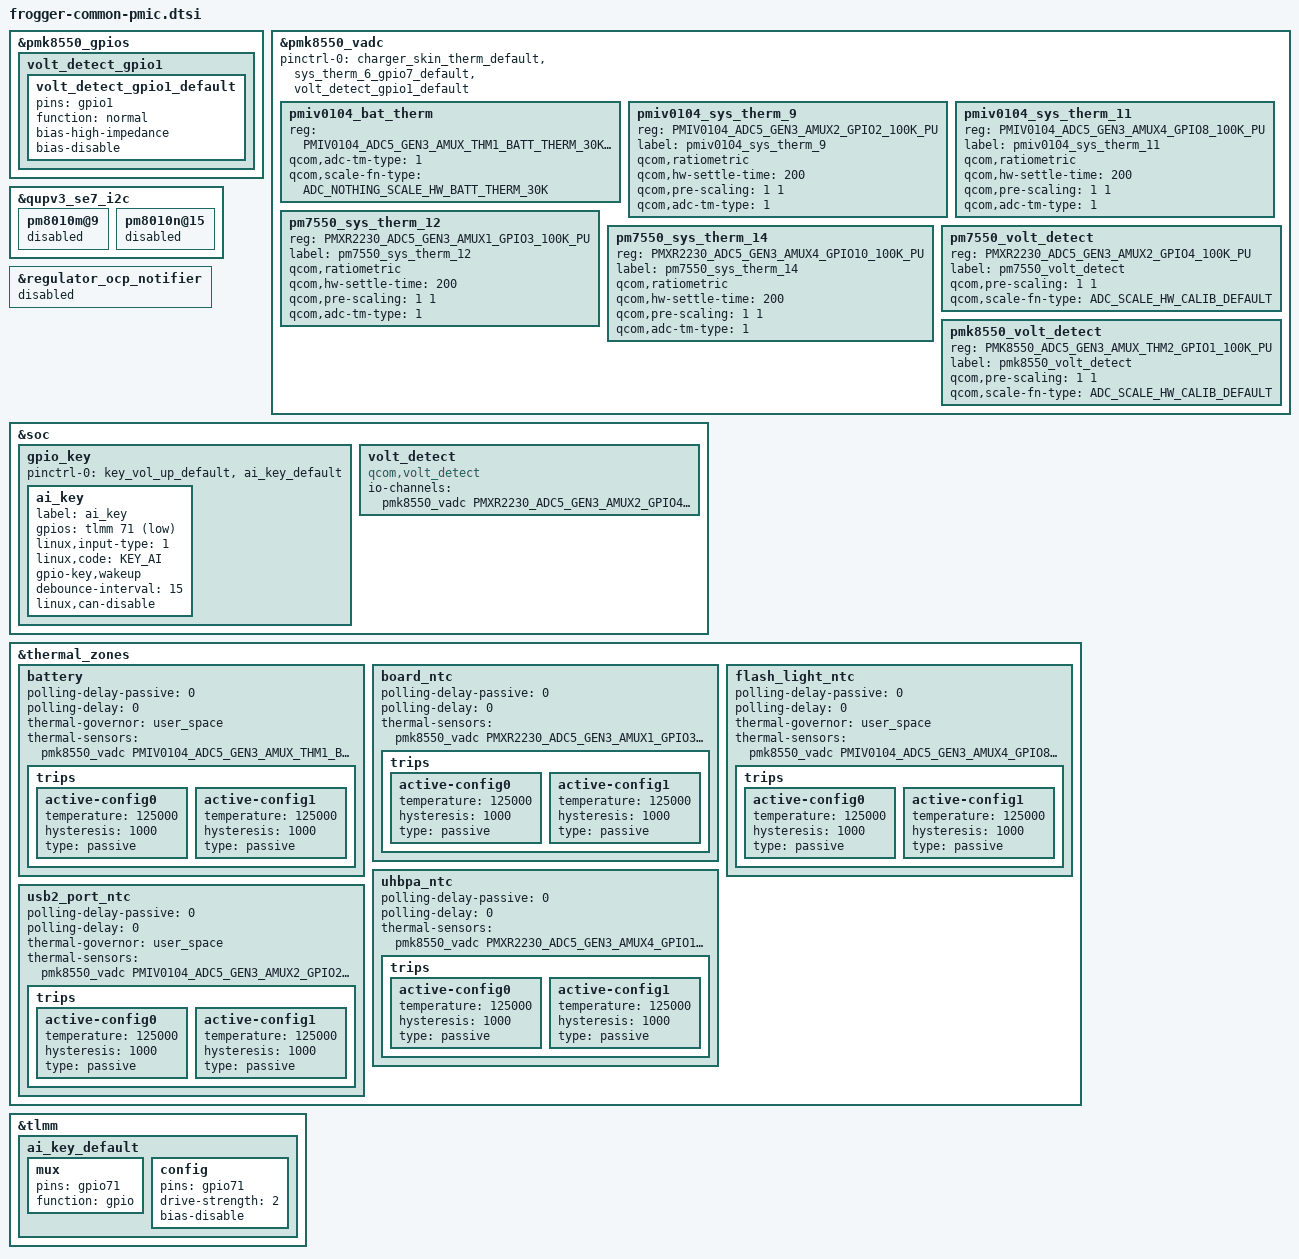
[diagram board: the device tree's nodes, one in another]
#include <dt-bindings/iio/qcom,spmi-adc5-gen3-pmiv0104.h>
#include <dt-bindings/iio/qcom,spmi-adc5-gen3-pmk8550.h>
#include <dt-bindings/iio/qcom,spmi-adc5-gen3-pmxr2230.h>
#include <dt-bindings/iio/qcom,spmi-vadc.h>
#include <dt-bindings/input/input.h>

&pmk8550_gpios {
	volt_detect_gpio1 {
		volt_detect_gpio1_default: volt_detect_gpio1_default {
			pins = "gpio1";
			function = "normal";
			bias-high-impedance;
			bias-disable;
		};
	};
};

&pmk8550_vadc {
	pinctrl-0 = <&charger_skin_therm_default &sys_therm_6_gpio7_default &volt_detect_gpio1_default>;

	pmiv0104_bat_therm {
		reg = <PMIV0104_ADC5_GEN3_AMUX_THM1_BATT_THERM_30K_PU>;
		qcom,adc-tm-type = <1>;
		qcom,scale-fn-type = <ADC_NOTHING_SCALE_HW_BATT_THERM_30K>;
	};

	pmiv0104_sys_therm_9 {
		reg = <PMIV0104_ADC5_GEN3_AMUX2_GPIO2_100K_PU>;
		label = "pmiv0104_sys_therm_9";
		qcom,ratiometric;
		qcom,hw-settle-time = <200>;
		qcom,pre-scaling = <1 1>;
		qcom,adc-tm-type = <1>;
	};

	pmiv0104_sys_therm_11 {
		reg = <PMIV0104_ADC5_GEN3_AMUX4_GPIO8_100K_PU>;
		label = "pmiv0104_sys_therm_11";
		qcom,ratiometric;
		qcom,hw-settle-time = <200>;
		qcom,pre-scaling = <1 1>;
		qcom,adc-tm-type = <1>;
	};

	pm7550_sys_therm_12 {
		reg = <PMXR2230_ADC5_GEN3_AMUX1_GPIO3_100K_PU>;
		label = "pm7550_sys_therm_12";
		qcom,ratiometric;
		qcom,hw-settle-time = <200>;
		qcom,pre-scaling = <1 1>;
		qcom,adc-tm-type = <1>;
	};

	pm7550_sys_therm_14 {
		reg = <PMXR2230_ADC5_GEN3_AMUX4_GPIO10_100K_PU>;
		label = "pm7550_sys_therm_14";
		qcom,ratiometric;
		qcom,hw-settle-time = <200>;
		qcom,pre-scaling = <1 1>;
		qcom,adc-tm-type = <1>;
	};

	pm7550_volt_detect {
		reg = <PMXR2230_ADC5_GEN3_AMUX2_GPIO4_100K_PU>;
		label = "pm7550_volt_detect";
		qcom,pre-scaling = <1 1>;
		qcom,scale-fn-type = <ADC_SCALE_HW_CALIB_DEFAULT>;
	};

	pmk8550_volt_detect {
		reg = <PMK8550_ADC5_GEN3_AMUX_THM2_GPIO1_100K_PU>;
		label = "pmk8550_volt_detect";
		qcom,pre-scaling = <1 1>;
		qcom,scale-fn-type = <ADC_SCALE_HW_CALIB_DEFAULT>;
	};
};

&qupv3_se7_i2c {
	pm8010m@9 {
		status = "disabled";
	};

	pm8010n@15 {
		status = "disabled";
	};
};

&regulator_ocp_notifier {
	status = "disabled";
};

&soc {
	gpio_key {
		pinctrl-0 = <&key_vol_up_default &ai_key_default>;

		ai_key {
			label = "ai_key";
			gpios = <&tlmm 71 GPIO_ACTIVE_LOW>;
			linux,input-type = <1>;
			linux,code = <KEY_AI>;
			gpio-key,wakeup;
			debounce-interval = <15>;
			linux,can-disable;
		};
	};

	volt_detect {
		compatible = "qcom,volt_detect";
		io-channels = <&pmk8550_vadc PMXR2230_ADC5_GEN3_AMUX2_GPIO4_100K_PU>;
		io-channel-names = "gpio4_voltage";
	};
};

&thermal_zones {
	/delete-node/ sys-therm-1;
	/delete-node/ sys-therm-2;
	/delete-node/ sys-therm-3;
	/delete-node/ sys-therm-4;
	/delete-node/ sys-therm-5;
	/delete-node/ sys-therm-6;
	/delete-node/ sys-therm-7;
	/delete-node/ sys-therm-10;

	/*
	 * Those /delete-node/ lines do nothing. This is a /plugin/ overlay and an
	 * overlay cannot delete a node from the base DTB, so every sys-therm-* it
	 * names survives in volcano.dtb regardless.
	 *
	 * Eight friendlier-named zones used to be defined below to replace them --
	 * ap_ntc, cam_ntc, gsmpa_ntc, ltepa_ntc, nrpa_ntc, sc_buck_ntc, usb_port_ntc
	 * and wifi_ntc, one for each /delete-node/ above. Each was a byte-for-byte
	 * copy of the base zone it shadowed, differing only in name, and each
	 * claimed an ADC channel a surviving base zone already owned, so none of
	 * them ever registered. They were pure dead weight.
	 *
	 * nrpa_ntc was worse than dead: it redefined display_test_config1..4, so
	 * the base sys-therm-5's own cooling-maps resolved to trips inside the
	 * copy. Trips must belong to the zone that maps them, so every bind failed
	 * and thermal_zone47 logged -ENXIO against each cooling device, 36 times a
	 * boot.
	 *
	 * All eight are gone. The zones that remain below claim channels no base
	 * zone touches, which is why they are the ones that actually register.
	 */

	battery {
		polling-delay-passive = <0>;
		polling-delay = <0>;
		thermal-governor = "user_space";
		thermal-sensors = <&pmk8550_vadc PMIV0104_ADC5_GEN3_AMUX_THM1_BATT_THERM_30K_PU>;
		trips {
			active-config0 {
				temperature = <125000>;
				hysteresis = <1000>;
				type = "passive";
			};

			active-config1 {
				temperature = <125000>;
				hysteresis = <1000>;
				type = "passive";
			};
		};
	};

	board_ntc {
		polling-delay-passive = <0>;
		polling-delay = <0>;
		thermal-sensors = <&pmk8550_vadc PMXR2230_ADC5_GEN3_AMUX1_GPIO3_100K_PU>;
		trips {
			active-config0 {
				temperature = <125000>;
				hysteresis = <1000>;
				type = "passive";
			};

			active-config1 {
				temperature = <125000>;
				hysteresis = <1000>;
				type = "passive";
			};
		};
	};

	flash_light_ntc {
		polling-delay-passive = <0>;
		polling-delay = <0>;
		thermal-governor = "user_space";
		thermal-sensors = <&pmk8550_vadc PMIV0104_ADC5_GEN3_AMUX4_GPIO8_100K_PU>;
		trips {
			active-config0 {
				temperature = <125000>;
				hysteresis = <1000>;
				type = "passive";
			};

			active-config1 {
				temperature = <125000>;
				hysteresis = <1000>;
				type = "passive";
			};
		};
	};

	uhbpa_ntc {
		polling-delay-passive = <0>;
		polling-delay = <0>;
		thermal-sensors = <&pmk8550_vadc PMXR2230_ADC5_GEN3_AMUX4_GPIO10_100K_PU>;
		trips {
			active-config0 {
				temperature = <125000>;
				hysteresis = <1000>;
				type = "passive";
			};

			active-config1 {
				temperature = <125000>;
				hysteresis = <1000>;
				type = "passive";
			};
		};
	};

	usb2_port_ntc {
		polling-delay-passive = <0>;
		polling-delay = <0>;
		thermal-governor = "user_space";
		thermal-sensors = <&pmk8550_vadc PMIV0104_ADC5_GEN3_AMUX2_GPIO2_100K_PU>;
		trips {
			active-config0 {
				temperature = <125000>;
				hysteresis = <1000>;
				type = "passive";
			};

			active-config1 {
				temperature = <125000>;
				hysteresis = <1000>;
				type = "passive";
			};
		};
	};

};

&tlmm {
	ai_key_default:ai_key_default {
		mux {
			pins = "gpio71";
			function = "gpio";
		};
		config {
			pins = "gpio71";
			drive-strength = <2>;
			bias-disable;
		};
	};
};

